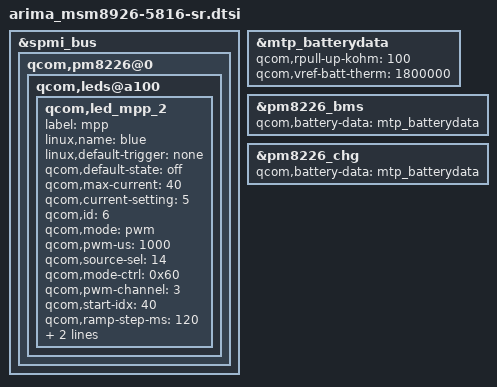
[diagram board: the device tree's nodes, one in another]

// [5816][LED][akenhsu] Remove blue LED of ER1 20150918 BEGIN
&spmi_bus {
	qcom,pm8226@0 {
		qcom,leds@a100 {
			status = "okay";
			qcom,led_mpp_2 {
				label = "mpp";
				linux,name = "blue";
				linux,default-trigger = "none";
				qcom,default-state = "off";
				qcom,max-current = <40>;
				qcom,current-setting = <5>;
				qcom,id = <6>;
				qcom,mode = "pwm";
				qcom,pwm-us = <1000>;
				qcom,source-sel = <14>;
				qcom,mode-ctrl = <0x60>;
				qcom,pwm-channel = <3>;
				qcom,start-idx = <40>;
				qcom,ramp-step-ms = <120>;
				qcom,duty-pcts = [00 00 50 99 99 99 50 00];
				qcom,use-blink;
			};
		};
	};
};
// [5816][LED][akenhsu] 20150918 END

/*[Arima_5816][bozhi_lin] move sr1 battery data to sr1 only 20150924 begin*/
&mtp_batterydata{
	qcom,rpull-up-kohm = <100>;
	qcom,vref-batt-therm = <1800000>;
	/include/ "batterydata-arima-4v2-2330mah-Lucisus2.dtsi"
};

&pm8226_bms {
	qcom,battery-data = <&mtp_batterydata>;
};

&pm8226_chg {
	qcom,battery-data = <&mtp_batterydata>;
};
/*[Arima_5816][bozhi_lin] 20150924 end*/

